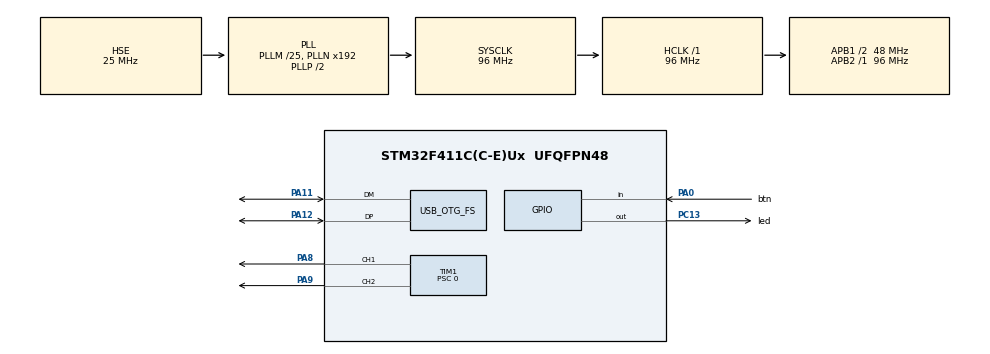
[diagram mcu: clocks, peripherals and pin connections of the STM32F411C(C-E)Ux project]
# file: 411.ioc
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Mcu.Family=STM32F4
RCC.CortexFreq_Value=96000000
TIM1.RepetitionCounter=9
PA11.Mode=Host_Only
Dma.TIM1_UP.0.Mode=DMA_CIRCULAR
TIM1.Pulse-PWM\ Generation1\ CH1=0
TIM1.OCFastMode_PWM-PWM\ Generation1\ CH1=TIM_OCFAST_DISABLE
RCC.SYSCLKSource=RCC_SYSCLKSOURCE_PLLCLK
ProjectManager.StackSize=0x400
Dma.TIM1_UP.0.MemInc=DMA_MINC_ENABLE
PA12.Signal=USB_OTG_FS_DP
TIM1.Prescaler=0
PH0\ -\ OSC_IN.Signal=RCC_OSC_IN
RCC.HCLKFreq_Value=96000000
RCC.APB2TimFreq_Value=96000000
USB_HOST0.BSP.ip=GPIO
RCC.AHBFreq_Value=96000000
RCC.HSE_VALUE=25000000
USB_OTG_FS.phy_itface=HCD_PHY_EMBEDDED
PB3.Mode=Trace_Asynchronous_SW
PC13-ANTI_TAMP.Signal=GPIO_Output
USB_HOST.USBH_MAX_DATA_BUFFER=512
TIM1.Channel-PWM\ Generation1\ CH1=TIM_CHANNEL_1
PA14.Mode=Trace_Asynchronous_SW
FATFS._USE_MKFS=0
PA8.Signal=S_TIM1_CH1
VP_TIM1_VS_ClockSourceINT.Mode=Internal
USB_HOST0.BSP.i2caddr=0
Mcu.Package=UFQFPN48
Dma.TIM1_UP.0.Direction=DMA_MEMORY_TO_PERIPH
NVIC.OTG_FS_IRQn=true\:1\:0\:true\:false\:true\:false\:true
USB_OTG_FS.VirtualMode=Host_Only
USB_HOST0.BSP.name=Drive_VBUS_FS
FATFS._FS_LOCK=0
RCC.APB1TimFreq_Value=96000000
FATFS._FS_RPATH=2
TIM1.Period=249
Dma.Request0=TIM1_UP
PA8.GPIO_Speed=GPIO_SPEED_FREQ_VERY_HIGH
PC13-ANTI_TAMP.GPIO_Label=led
VP_USB_HOST_VS_USB_HOST_MSC_FS.Mode=MSC_FS
PH1\ -\ OSC_OUT.Mode=HSE-External-Oscillator
USB_HOST0.BSP.solution=PC13-ANTI_TAMP
USB_HOST.BSP.number=1
RCC.APB1CLKDivider=RCC_HCLK_DIV2
PA0-WKUP.GPIO_Label=btn
PA0-WKUP.Signal=GPIO_Input
USB_HOST0.BSP.STBoard=false
PA13.Signal=SYS_JTMS-SWDIO
TIM1.AutoReloadPreload=TIM_AUTORELOAD_PRELOAD_DISABLE
Dma.TIM1_UP.0.PeriphDataAlignment=DMA_PDATAALIGN_HALFWORD
PH0\ -\ OSC_IN.Mode=HSE-External-Oscillator
SH.S_TIM1_CH1.0=TIM1_CH1,PWM Generation1 CH1
ProjectManager.TargetToolchain=STM32CubeIDE
PA9.Signal=S_TIM1_CH2
TIM1.Channel-PWM\ Generation2\ CH2=TIM_CHANNEL_2
Dma.TIM1_UP.0.Priority=DMA_PRIORITY_HIGH
RCC.LSE_VALUE=32768
PH1\ -\ OSC_OUT.Signal=RCC_OSC_OUT
board=custom
RCC.VCOOutputFreq_Value=192000000
USB_HOST.VirtualModeFS=Msc
Dma.TIM1_UP.0.Instance=DMA2_Stream5
TIM1.TIM_MasterOutputTrigger=TIM_TRGO_UPDATE
RCC.APB2Freq_Value=96000000
USB_HOST0.BSP.api=Unknown
SH.S_TIM1_CH2.0=TIM1_CH2,PWM Generation2 CH2
NVIC.DMA2_Stream5_IRQn=true\:2\:0\:true\:false\:true\:false\:true
FATFS._USE_FIND=1
PA13.Mode=Trace_Asynchronous_SW
Dma.TIM1_UP.0.PeriphInc=DMA_PINC_DISABLE
Mcu.Name=STM32F411C(C-E)Ux
FATFS._MAX_SS=512
RCC.48MHZClocksFreq_Value=48000000
PB3.Signal=SYS_JTDO-SWO
RCC.SYSCLKFreq_VALUE=96000000
PA12.Mode=Host_Only
PA11.Signal=USB_OTG_FS_DM
PA14.Signal=SYS_JTCK-SWCLK
USB_HOST.USBH_MAX_SIZE_CONFIGURATION=512
ProjectManager.HeapSize=0x400
VP_FATFS_VS_USB.Mode=USB
Dma.TIM1_UP.0.MemDataAlignment=DMA_MDATAALIGN_HALFWORD
RCC.HSI_VALUE=16000000
PA8.GPIO_PuPd=GPIO_NOPULL
USB_HOST.USBH_HandleTypeDef=hUsbHostFS
NVIC.PriorityGroup=NVIC_PRIORITYGROUP_4
RCC.PLLM=25
PA9.GPIO_Speed=GPIO_SPEED_FREQ_VERY_HIGH
FATFS._FS_READONLY=0
RCC.APB1Freq_Value=48000000
VP_CRC_VS_CRC.Mode=CRC_Activate
USB_HOST0.BSP.mode=Output
Dma.TIM1_UP.0.FIFOMode=DMA_FIFOMODE_DISABLE
USB_HOST0.BSP.instance=PC13-ANTI_TAMP

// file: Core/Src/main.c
/* USER CODE BEGIN Header */
/**
  ******************************************************************************
  * @file           : main.c
  * @brief          : Main program body
  ******************************************************************************
  * @attention
  *
  * <h2><center>&copy; Copyright (c) 2021 STMicroelectronics.
  * All rights reserved.</center></h2>
  *
  * This software component is licensed by ST under Ultimate Liberty license
  * SLA0044, the "License"; You may not use this file except in compliance with
  * the License. You may obtain a copy of the License at:
  *                             www.st.com/SLA0044
  *
  ******************************************************************************
  */
/* USER CODE END Header */
#include "main.h"
#include "fatfs.h"
#include "usb_host.h"

/* USER CODE BEGIN Includes */
//#include "mp3.h"
#include "files.h"
#include "pwmAudio.h"

/* USER CODE END Includes */

CRC_HandleTypeDef hcrc;

TIM_HandleTypeDef htim1;
DMA_HandleTypeDef hdma_tim1_up;

void SystemClock_Config(void);
static void MX_GPIO_Init(void);
static void MX_DMA_Init(void);
static void MX_TIM1_Init(void);
static void MX_CRC_Init(void);
void MX_USB_HOST_Process(void);

/* USER CODE BEGIN PFP */
int _write(int32_t file, uint8_t *ptr, int32_t len)
{
	for (int i = 0; i < len; i++)
	{
		ITM_SendChar(*ptr++);
	}
	return len;
}

/* USER CODE END PFP */

int main(void)
{

  /* MCU Configuration--------------------------------------------------------*/

  /* Reset of all peripherals, Initializes the Flash interface and the Systick. */
  HAL_Init();

  /* Configure the system clock */
  SystemClock_Config();

  /* Initialize all configured peripherals */
  MX_GPIO_Init();
  MX_DMA_Init();
  MX_TIM1_Init();
  MX_CRC_Init();
  MX_USB_HOST_Init();
  MX_FATFS_Init();
  /* USER CODE BEGIN 2 */
  printf("System Init\n");
  /* USER CODE END 2 */

  /* Infinite loop */
  /* USER CODE BEGIN WHILE */
  while (1)
  {
	  handleFS();
	  handleAudio();
    /* USER CODE END WHILE */
    MX_USB_HOST_Process();

  }
}

void SystemClock_Config(void)
{
  RCC_OscInitTypeDef RCC_OscInitStruct = {0};
  RCC_ClkInitTypeDef RCC_ClkInitStruct = {0};

  /** Configure the main internal regulator output voltage
  */
  __HAL_RCC_PWR_CLK_ENABLE();
  __HAL_PWR_VOLTAGESCALING_CONFIG(PWR_REGULATOR_VOLTAGE_SCALE1);
  /** Initializes the RCC Oscillators according to the specified parameters
  * in the RCC_OscInitTypeDef structure.
  */
  RCC_OscInitStruct.OscillatorType = RCC_OSCILLATORTYPE_HSE;
  RCC_OscInitStruct.HSEState = RCC_HSE_ON;
  RCC_OscInitStruct.PLL.PLLState = RCC_PLL_ON;
  RCC_OscInitStruct.PLL.PLLSource = RCC_PLLSOURCE_HSE;
  RCC_OscInitStruct.PLL.PLLM = 25;
  RCC_OscInitStruct.PLL.PLLN = 192;
  RCC_OscInitStruct.PLL.PLLP = RCC_PLLP_DIV2;
  RCC_OscInitStruct.PLL.PLLQ = 4;
  if (HAL_RCC_OscConfig(&RCC_OscInitStruct) != HAL_OK)
  {
    Error_Handler();
  }
  /** Initializes the CPU, AHB and APB buses clocks
  */
  RCC_ClkInitStruct.ClockType = RCC_CLOCKTYPE_HCLK|RCC_CLOCKTYPE_SYSCLK
                              |RCC_CLOCKTYPE_PCLK1|RCC_CLOCKTYPE_PCLK2;
  RCC_ClkInitStruct.SYSCLKSource = RCC_SYSCLKSOURCE_PLLCLK;
  RCC_ClkInitStruct.AHBCLKDivider = RCC_SYSCLK_DIV1;
  RCC_ClkInitStruct.APB1CLKDivider = RCC_HCLK_DIV2;
  RCC_ClkInitStruct.APB2CLKDivider = RCC_HCLK_DIV1;

  if (HAL_RCC_ClockConfig(&RCC_ClkInitStruct, FLASH_LATENCY_3) != HAL_OK)
  {
    Error_Handler();
  }
}

static void MX_CRC_Init(void)
{

  hcrc.Instance = CRC;
  if (HAL_CRC_Init(&hcrc) != HAL_OK)
  {
    Error_Handler();
  }

}

static void MX_TIM1_Init(void)
{

  TIM_ClockConfigTypeDef sClockSourceConfig = {0};
  TIM_MasterConfigTypeDef sMasterConfig = {0};
  TIM_OC_InitTypeDef sConfigOC = {0};
  TIM_BreakDeadTimeConfigTypeDef sBreakDeadTimeConfig = {0};

  htim1.Instance = TIM1;
  htim1.Init.Prescaler = 0;
  htim1.Init.CounterMode = TIM_COUNTERMODE_UP;
  htim1.Init.Period = 249;
  htim1.Init.ClockDivision = TIM_CLOCKDIVISION_DIV1;
  htim1.Init.RepetitionCounter = 9;
  htim1.Init.AutoReloadPreload = TIM_AUTORELOAD_PRELOAD_DISABLE;
  if (HAL_TIM_Base_Init(&htim1) != HAL_OK)
  {
    Error_Handler();
  }
  sClockSourceConfig.ClockSource = TIM_CLOCKSOURCE_INTERNAL;
  if (HAL_TIM_ConfigClockSource(&htim1, &sClockSourceConfig) != HAL_OK)
  {
    Error_Handler();
  }
  if (HAL_TIM_PWM_Init(&htim1) != HAL_OK)
  {
    Error_Handler();
  }
  sMasterConfig.MasterOutputTrigger = TIM_TRGO_UPDATE;
  sMasterConfig.MasterSlaveMode = TIM_MASTERSLAVEMODE_DISABLE;
  if (HAL_TIMEx_MasterConfigSynchronization(&htim1, &sMasterConfig) != HAL_OK)
  {
    Error_Handler();
  }
  sConfigOC.OCMode = TIM_OCMODE_PWM1;
  sConfigOC.Pulse = 0;
  sConfigOC.OCPolarity = TIM_OCPOLARITY_HIGH;
  sConfigOC.OCNPolarity = TIM_OCNPOLARITY_HIGH;
  sConfigOC.OCFastMode = TIM_OCFAST_DISABLE;
  sConfigOC.OCIdleState = TIM_OCIDLESTATE_RESET;
  sConfigOC.OCNIdleState = TIM_OCNIDLESTATE_RESET;
  if (HAL_TIM_PWM_ConfigChannel(&htim1, &sConfigOC, TIM_CHANNEL_1) != HAL_OK)
  {
    Error_Handler();
  }
  if (HAL_TIM_PWM_ConfigChannel(&htim1, &sConfigOC, TIM_CHANNEL_2) != HAL_OK)
  {
    Error_Handler();
  }
  sBreakDeadTimeConfig.OffStateRunMode = TIM_OSSR_DISABLE;
  sBreakDeadTimeConfig.OffStateIDLEMode = TIM_OSSI_DISABLE;
  sBreakDeadTimeConfig.LockLevel = TIM_LOCKLEVEL_OFF;
  sBreakDeadTimeConfig.DeadTime = 0;
  sBreakDeadTimeConfig.BreakState = TIM_BREAK_DISABLE;
  sBreakDeadTimeConfig.BreakPolarity = TIM_BREAKPOLARITY_HIGH;
  sBreakDeadTimeConfig.AutomaticOutput = TIM_AUTOMATICOUTPUT_DISABLE;
  if (HAL_TIMEx_ConfigBreakDeadTime(&htim1, &sBreakDeadTimeConfig) != HAL_OK)
  {
    Error_Handler();
  }
  HAL_TIM_MspPostInit(&htim1);

}

static void MX_DMA_Init(void)
{

  /* DMA controller clock enable */
  __HAL_RCC_DMA2_CLK_ENABLE();

  /* DMA interrupt init */
  /* DMA2_Stream5_IRQn interrupt configuration */
  HAL_NVIC_SetPriority(DMA2_Stream5_IRQn, 2, 0);
  HAL_NVIC_EnableIRQ(DMA2_Stream5_IRQn);

}

static void MX_GPIO_Init(void)
{
  GPIO_InitTypeDef GPIO_InitStruct = {0};

  /* GPIO Ports Clock Enable */
  __HAL_RCC_GPIOC_CLK_ENABLE();
  __HAL_RCC_GPIOH_CLK_ENABLE();
  __HAL_RCC_GPIOA_CLK_ENABLE();
  __HAL_RCC_GPIOB_CLK_ENABLE();

  /*Configure GPIO pin Output Level */
  HAL_GPIO_WritePin(led_GPIO_Port, led_Pin, GPIO_PIN_RESET);

  /*Configure GPIO pin : led_Pin */
  GPIO_InitStruct.Pin = led_Pin;
  GPIO_InitStruct.Mode = GPIO_MODE_OUTPUT_PP;
  GPIO_InitStruct.Pull = GPIO_NOPULL;
  GPIO_InitStruct.Speed = GPIO_SPEED_FREQ_LOW;
  HAL_GPIO_Init(led_GPIO_Port, &GPIO_InitStruct);

  /*Configure GPIO pin : btn_Pin */
  GPIO_InitStruct.Pin = btn_Pin;
  GPIO_InitStruct.Mode = GPIO_MODE_INPUT;
  GPIO_InitStruct.Pull = GPIO_NOPULL;
  HAL_GPIO_Init(btn_GPIO_Port, &GPIO_InitStruct);

}

void Error_Handler(void)
{
  __disable_irq();
  while (1)
  {
  }
}

/************************ (C) COPYRIGHT STMicroelectronics *****END OF FILE****/
